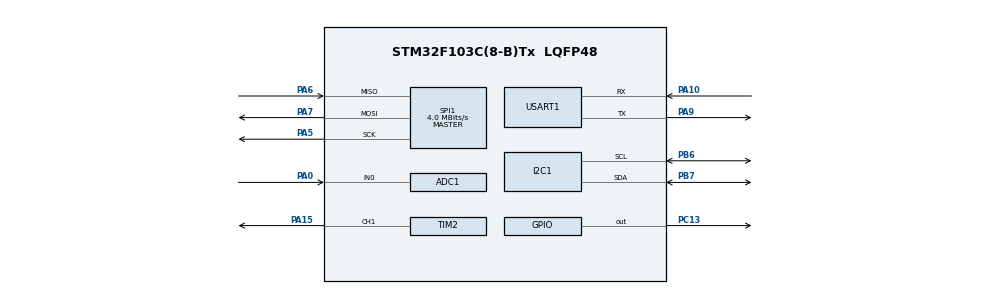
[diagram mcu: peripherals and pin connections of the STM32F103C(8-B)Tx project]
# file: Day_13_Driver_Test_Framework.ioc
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ADC1.Channel-0\#ChannelRegularConversion=ADC_CHANNEL_0
ADC1.NbrOfConversionFlag=1
ADC1.Rank-0\#ChannelRegularConversion=1
ADC1.SamplingTime-0\#ChannelRegularConversion=ADC_SAMPLETIME_1CYCLE_5
ADC1.master=1
Mcu.Family=STM32F1
Mcu.Name=STM32F103C(8-B)Tx
Mcu.Package=LQFP48
NVIC.PriorityGroup=NVIC_PRIORITYGROUP_4
PA0-WKUP.Signal=ADCx_IN0
PA10.Mode=Asynchronous
PA10.Signal=USART1_RX
PA15.Signal=S_TIM2_CH1_ETR
PA5.Mode=Full_Duplex_Master
PA5.Signal=SPI1_SCK
PA6.Mode=Full_Duplex_Master
PA6.Signal=SPI1_MISO
PA7.Mode=Full_Duplex_Master
PA7.Signal=SPI1_MOSI
PA9.Mode=Asynchronous
PA9.Signal=USART1_TX
PB6.Mode=I2C
PB6.Signal=I2C1_SCL
PB7.Mode=I2C
PB7.Signal=I2C1_SDA
PC13-TAMPER-RTC.Signal=GPIO_Output
ProjectManager.HeapSize=0x200
ProjectManager.StackSize=0x400
ProjectManager.TargetToolchain=STM32CubeIDE
RCC.APB1Freq_Value=8000000
RCC.APB2Freq_Value=8000000
SH.ADCx_IN0.0=ADC1_IN0,IN0
SH.S_TIM2_CH1_ETR.0=TIM2_CH1,PWM Generation1 CH1
SPI1.CalculateBaudRate=4.0 MBits/s
SPI1.Direction=SPI_DIRECTION_2LINES
SPI1.Mode=SPI_MODE_MASTER
SPI1.VirtualType=VM_MASTER
TIM2.Channel-PWM\ Generation1\ CH1=TIM_CHANNEL_1
USART1.VirtualMode=VM_ASYNC
VP_SYS_VS_ND.Mode=No_Debug
VP_TIM2_VS_ClockSourceINT.Mode=Internal
board=custom

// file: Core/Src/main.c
/* USER CODE BEGIN Header */
/**
  ******************************************************************************
  * @file           : main.c
  * @brief          : Main program body
  ******************************************************************************
  * @attention
  *
  * Copyright (c) 2026 STMicroelectronics.
  * All rights reserved.
  *
  * This software is licensed under terms that can be found in the LICENSE file
  * in the root directory of this software component.
  * If no LICENSE file comes with this software, it is provided AS-IS.
  *
  ******************************************************************************
  */
/* USER CODE END Header */
#include "main.h"
#include "gpio_driver.h"
#include "uart_driver.h"
#include "adc_driver.h"
#include "timer_driver.h"
#include "pwm_driver.h"
#include "spi_driver.h"
#include "i2c_driver.h"
#include "test_framework.h"

#include <stdio.h>

ADC_HandleTypeDef hadc1;

I2C_HandleTypeDef hi2c1;

SPI_HandleTypeDef hspi1;

TIM_HandleTypeDef htim2;

UART_HandleTypeDef huart1;

void SystemClock_Config(void);
static void MX_GPIO_Init(void);
static void MX_ADC1_Init(void);
static void MX_I2C1_Init(void);
static void MX_SPI1_Init(void);
static void MX_TIM2_Init(void);
static void MX_USART1_UART_Init(void);

int main(void)
{

  /* MCU Configuration--------------------------------------------------------*/

  /* Reset of all peripherals, Initializes the Flash interface and the Systick. */
  HAL_Init();

  /* Configure the system clock */
  SystemClock_Config();

  /* Initialize all configured peripherals */
  MX_GPIO_Init();
  MX_ADC1_Init();
  MX_I2C1_Init();
  MX_SPI1_Init();
  MX_TIM2_Init();
  MX_USART1_UART_Init();
  /* USER CODE BEGIN 2 */
  UART_Transmit(&huart1,
  "\r\n===== STM32 DRIVER TEST FRAMEWORK =====\r\n");
  /* USER CODE END 2 */

  /* Infinite loop */
  /* USER CODE BEGIN WHILE */
  while (1)
  {
      Driver_Test_Run();
      HAL_Delay(3000);
  }
  /* USER CODE END 3 */
}

void SystemClock_Config(void)
{
  RCC_OscInitTypeDef RCC_OscInitStruct = {0};
  RCC_ClkInitTypeDef RCC_ClkInitStruct = {0};
  RCC_PeriphCLKInitTypeDef PeriphClkInit = {0};

  /** Initializes the RCC Oscillators according to the specified parameters
  * in the RCC_OscInitTypeDef structure.
  */
  RCC_OscInitStruct.OscillatorType = RCC_OSCILLATORTYPE_HSI;
  RCC_OscInitStruct.HSIState = RCC_HSI_ON;
  RCC_OscInitStruct.HSICalibrationValue = RCC_HSICALIBRATION_DEFAULT;
  RCC_OscInitStruct.PLL.PLLState = RCC_PLL_NONE;
  if (HAL_RCC_OscConfig(&RCC_OscInitStruct) != HAL_OK)
  {
    Error_Handler();
  }

  /** Initializes the CPU, AHB and APB buses clocks
  */
  RCC_ClkInitStruct.ClockType = RCC_CLOCKTYPE_HCLK|RCC_CLOCKTYPE_SYSCLK
                              |RCC_CLOCKTYPE_PCLK1|RCC_CLOCKTYPE_PCLK2;
  RCC_ClkInitStruct.SYSCLKSource = RCC_SYSCLKSOURCE_HSI;
  RCC_ClkInitStruct.AHBCLKDivider = RCC_SYSCLK_DIV1;
  RCC_ClkInitStruct.APB1CLKDivider = RCC_HCLK_DIV1;
  RCC_ClkInitStruct.APB2CLKDivider = RCC_HCLK_DIV1;

  if (HAL_RCC_ClockConfig(&RCC_ClkInitStruct, FLASH_LATENCY_0) != HAL_OK)
  {
    Error_Handler();
  }
  PeriphClkInit.PeriphClockSelection = RCC_PERIPHCLK_ADC;
  PeriphClkInit.AdcClockSelection = RCC_ADCPCLK2_DIV2;
  if (HAL_RCCEx_PeriphCLKConfig(&PeriphClkInit) != HAL_OK)
  {
    Error_Handler();
  }
}

static void MX_ADC1_Init(void)
{

  ADC_ChannelConfTypeDef sConfig = {0};

  /** Common config
  */
  hadc1.Instance = ADC1;
  hadc1.Init.ScanConvMode = ADC_SCAN_DISABLE;
  hadc1.Init.ContinuousConvMode = DISABLE;
  hadc1.Init.DiscontinuousConvMode = DISABLE;
  hadc1.Init.ExternalTrigConv = ADC_SOFTWARE_START;
  hadc1.Init.DataAlign = ADC_DATAALIGN_RIGHT;
  hadc1.Init.NbrOfConversion = 1;
  if (HAL_ADC_Init(&hadc1) != HAL_OK)
  {
    Error_Handler();
  }

  /** Configure Regular Channel
  */
  sConfig.Channel = ADC_CHANNEL_0;
  sConfig.Rank = ADC_REGULAR_RANK_1;
  sConfig.SamplingTime = ADC_SAMPLETIME_1CYCLE_5;
  if (HAL_ADC_ConfigChannel(&hadc1, &sConfig) != HAL_OK)
  {
    Error_Handler();
  }

}

static void MX_I2C1_Init(void)
{

  hi2c1.Instance = I2C1;
  hi2c1.Init.ClockSpeed = 100000;
  hi2c1.Init.DutyCycle = I2C_DUTYCYCLE_2;
  hi2c1.Init.OwnAddress1 = 0;
  hi2c1.Init.AddressingMode = I2C_ADDRESSINGMODE_7BIT;
  hi2c1.Init.DualAddressMode = I2C_DUALADDRESS_DISABLE;
  hi2c1.Init.OwnAddress2 = 0;
  hi2c1.Init.GeneralCallMode = I2C_GENERALCALL_DISABLE;
  hi2c1.Init.NoStretchMode = I2C_NOSTRETCH_DISABLE;
  if (HAL_I2C_Init(&hi2c1) != HAL_OK)
  {
    Error_Handler();
  }

}

static void MX_SPI1_Init(void)
{

  /* SPI1 parameter configuration*/
  hspi1.Instance = SPI1;
  hspi1.Init.Mode = SPI_MODE_MASTER;
  hspi1.Init.Direction = SPI_DIRECTION_2LINES;
  hspi1.Init.DataSize = SPI_DATASIZE_8BIT;
  hspi1.Init.CLKPolarity = SPI_POLARITY_LOW;
  hspi1.Init.CLKPhase = SPI_PHASE_1EDGE;
  hspi1.Init.NSS = SPI_NSS_SOFT;
  hspi1.Init.BaudRatePrescaler = SPI_BAUDRATEPRESCALER_2;
  hspi1.Init.FirstBit = SPI_FIRSTBIT_MSB;
  hspi1.Init.TIMode = SPI_TIMODE_DISABLE;
  hspi1.Init.CRCCalculation = SPI_CRCCALCULATION_DISABLE;
  hspi1.Init.CRCPolynomial = 10;
  if (HAL_SPI_Init(&hspi1) != HAL_OK)
  {
    Error_Handler();
  }

}

static void MX_TIM2_Init(void)
{

  TIM_ClockConfigTypeDef sClockSourceConfig = {0};
  TIM_MasterConfigTypeDef sMasterConfig = {0};
  TIM_OC_InitTypeDef sConfigOC = {0};

  htim2.Instance = TIM2;
  htim2.Init.Prescaler = 0;
  htim2.Init.CounterMode = TIM_COUNTERMODE_UP;
  htim2.Init.Period = 65535;
  htim2.Init.ClockDivision = TIM_CLOCKDIVISION_DIV1;
  htim2.Init.AutoReloadPreload = TIM_AUTORELOAD_PRELOAD_DISABLE;
  if (HAL_TIM_Base_Init(&htim2) != HAL_OK)
  {
    Error_Handler();
  }
  sClockSourceConfig.ClockSource = TIM_CLOCKSOURCE_INTERNAL;
  if (HAL_TIM_ConfigClockSource(&htim2, &sClockSourceConfig) != HAL_OK)
  {
    Error_Handler();
  }
  if (HAL_TIM_PWM_Init(&htim2) != HAL_OK)
  {
    Error_Handler();
  }
  sMasterConfig.MasterOutputTrigger = TIM_TRGO_RESET;
  sMasterConfig.MasterSlaveMode = TIM_MASTERSLAVEMODE_DISABLE;
  if (HAL_TIMEx_MasterConfigSynchronization(&htim2, &sMasterConfig) != HAL_OK)
  {
    Error_Handler();
  }
  sConfigOC.OCMode = TIM_OCMODE_PWM1;
  sConfigOC.Pulse = 0;
  sConfigOC.OCPolarity = TIM_OCPOLARITY_HIGH;
  sConfigOC.OCFastMode = TIM_OCFAST_DISABLE;
  if (HAL_TIM_PWM_ConfigChannel(&htim2, &sConfigOC, TIM_CHANNEL_1) != HAL_OK)
  {
    Error_Handler();
  }
  HAL_TIM_MspPostInit(&htim2);

}

static void MX_USART1_UART_Init(void)
{

  huart1.Instance = USART1;
  huart1.Init.BaudRate = 115200;
  huart1.Init.WordLength = UART_WORDLENGTH_8B;
  huart1.Init.StopBits = UART_STOPBITS_1;
  huart1.Init.Parity = UART_PARITY_NONE;
  huart1.Init.Mode = UART_MODE_TX_RX;
  huart1.Init.HwFlowCtl = UART_HWCONTROL_NONE;
  huart1.Init.OverSampling = UART_OVERSAMPLING_16;
  if (HAL_UART_Init(&huart1) != HAL_OK)
  {
    Error_Handler();
  }

}

static void MX_GPIO_Init(void)
{
  GPIO_InitTypeDef GPIO_InitStruct = {0};

  /* GPIO Ports Clock Enable */
  __HAL_RCC_GPIOC_CLK_ENABLE();
  __HAL_RCC_GPIOA_CLK_ENABLE();
  __HAL_RCC_GPIOB_CLK_ENABLE();

  /*Configure GPIO pin Output Level */
  HAL_GPIO_WritePin(GPIOC, GPIO_PIN_13, GPIO_PIN_RESET);

  /*Configure GPIO pin : PC13 */
  GPIO_InitStruct.Pin = GPIO_PIN_13;
  GPIO_InitStruct.Mode = GPIO_MODE_OUTPUT_PP;
  GPIO_InitStruct.Pull = GPIO_NOPULL;
  GPIO_InitStruct.Speed = GPIO_SPEED_FREQ_LOW;
  HAL_GPIO_Init(GPIOC, &GPIO_InitStruct);

}

void Error_Handler(void)
{
  __disable_irq();
  while (1)
  {
  }
}
